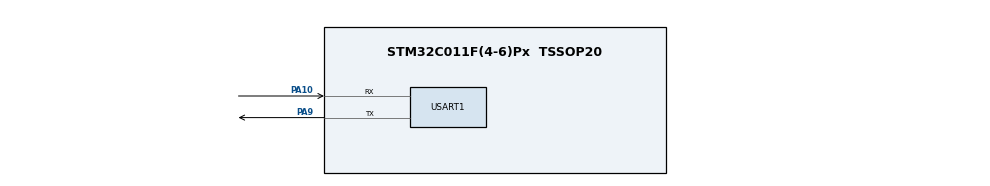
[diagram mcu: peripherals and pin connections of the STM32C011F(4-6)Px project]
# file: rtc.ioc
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Mcu.Family=STM32C0
Mcu.Name=STM32C011F(4-6)Px
Mcu.Package=TSSOP20
PA10\ [PA12].Mode=Asynchronous
PA10\ [PA12].Signal=USART1_RX
PA9\ [PA11].Mode=Asynchronous
PA9\ [PA11].Signal=USART1_TX
ProjectManager.HeapSize=0x200
ProjectManager.StackSize=0x400
ProjectManager.TargetToolchain=STM32CubeIDE
RCC.ADCFreq_Value=48000000
RCC.AHBFreq_Value=48000000
RCC.CortexFreq_Value=48000000
RCC.EXTERNAL_CLOCK_VALUE=12288000
RCC.HCLKFreq_Value=48000000
RCC.HSE_VALUE=8000000
RCC.HSISYSCLKDivider=RCC_HSI_DIV1
RCC.HSI_VALUE=48000000
RCC.SYSCLKFreq_VALUE=48000000
RTC.Format=RTC_FORMAT_BIN
USART1.VirtualMode-Asynchronous=VM_ASYNC
VP_RTC_VS_RTC_Activate.Mode=RTC_Enabled
VP_RTC_VS_RTC_Calendar.Mode=RTC_Calendar
VP_SYS_VS_PINREMAP.Mode=PINREMAP
VP_SYS_VS_PINREMAP_10_12.Mode=PINREMAP_10_12
board=custom

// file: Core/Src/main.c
/* USER CODE BEGIN Header */
/**
  ******************************************************************************
  * @file           : main.c
  * @brief          : Main program body
  ******************************************************************************
  * @attention
  *
  * Copyright (c) 2024 STMicroelectronics.
  * All rights reserved.
  *
  * This software is licensed under terms that can be found in the LICENSE file
  * in the root directory of this software component.
  * If no LICENSE file comes with this software, it is provided AS-IS.
  *
  ******************************************************************************
  */
/* USER CODE END Header */
#include "main.h"

/* USER CODE BEGIN Includes */
#include "stdio.h"
#include "string.h"
uint8_t dia, mes, ano, horas, segundos, minutos;
char uart_tx_buffer[50];

/* USER CODE END Includes */
RTC_HandleTypeDef hrtc;
UART_HandleTypeDef huart1;

/* USER CODE BEGIN PV */
RTC_DateTypeDef data;
RTC_TimeTypeDef tempo;
/* USER CODE END PV */
void SystemClock_Config(void);
static void MX_GPIO_Init(void);
static void MX_RTC_Init(void);
static void MX_USART1_UART_Init(void);
int main(void)
{
  /* MCU Configuration--------------------------------------------------------*/
  /* Reset of all peripherals, Initializes the Flash interface and the Systick. */
  HAL_Init();
  /* Configure the system clock */
  SystemClock_Config();
  /* Initialize all configured peripherals */
  MX_GPIO_Init();
  MX_RTC_Init();
  MX_USART1_UART_Init();
  /* USER CODE BEGIN 2 */
  /* Ajuste a data e a hora aqui */
   data.Year = 24;  // 2024
   data.Month = RTC_MONTH_JUNE;
   data.Date = 25;
   data.WeekDay = RTC_WEEKDAY_TUESDAY;
   tempo.Hours = 9;
   tempo.Minutes = 5;
   tempo.Seconds = 0;
   HAL_RTC_SetDate(&hrtc, &data, RTC_FORMAT_BIN);
   HAL_RTC_SetTime(&hrtc, &tempo, RTC_FORMAT_BIN);
  /* USER CODE END 2 */
  /* Infinite loop */
  while (1)
  {
    /* USER CODE BEGIN 3 */
	HAL_RTC_GetDate(&hrtc, &data, RTC_FORMAT_BIN);
	HAL_RTC_GetTime(&hrtc, &tempo, RTC_FORMAT_BIN);

	horas = tempo.Hours;
	minutos = tempo.Minutes;
	segundos = tempo.Seconds;
	dia = data.Date;
	mes = data.Month;
	ano = data.Year;
	sprintf(uart_tx_buffer, "Data: %02d/%02d/%04d Tempo: %02d:%02d:%02d\r\n", dia, mes, 2000+ano, horas, minutos, segundos);
	HAL_UART_Transmit(&huart1, (uint8_t *)uart_tx_buffer, strlen(uart_tx_buffer), 1000);
  }
  /* USER CODE END 3 */
}

void SystemClock_Config(void)
{
  RCC_OscInitTypeDef RCC_OscInitStruct = {0};
  RCC_ClkInitTypeDef RCC_ClkInitStruct = {0};

  /** Initializes the RCC Oscillators according to the specified parameters
  * in the RCC_OscInitTypeDef structure.
  */
  RCC_OscInitStruct.OscillatorType = RCC_OSCILLATORTYPE_HSI|RCC_OSCILLATORTYPE_LSI;
  RCC_OscInitStruct.HSIState = RCC_HSI_ON;
  RCC_OscInitStruct.HSIDiv = RCC_HSI_DIV1;
  RCC_OscInitStruct.HSICalibrationValue = RCC_HSICALIBRATION_DEFAULT;
  RCC_OscInitStruct.LSIState = RCC_LSI_ON;

  if (HAL_RCC_OscConfig(&RCC_OscInitStruct) != HAL_OK)
  {
    Error_Handler();
  }

  /** Initializes the CPU, AHB and APB buses clocks
  */
  RCC_ClkInitStruct.ClockType = RCC_CLOCKTYPE_HCLK|RCC_CLOCKTYPE_SYSCLK
                              |RCC_CLOCKTYPE_PCLK1;
  RCC_ClkInitStruct.SYSCLKSource = RCC_SYSCLKSOURCE_HSI;
  RCC_ClkInitStruct.SYSCLKDivider = RCC_SYSCLK_DIV1;
  RCC_ClkInitStruct.AHBCLKDivider = RCC_HCLK_DIV1;
  RCC_ClkInitStruct.APB1CLKDivider = RCC_APB1_DIV1;

  if (HAL_RCC_ClockConfig(&RCC_ClkInitStruct, FLASH_LATENCY_1) != HAL_OK)
  {
    Error_Handler();
  }
}

static void MX_RTC_Init(void)
{

  RTC_TimeTypeDef sTime = {0};
  RTC_DateTypeDef sDate = {0};

  /** Initialize RTC Only
  */
  hrtc.Instance = RTC;
  hrtc.Init.HourFormat = RTC_HOURFORMAT_24;
  hrtc.Init.AsynchPrediv = 127;
  hrtc.Init.SynchPrediv = 255;
  hrtc.Init.OutPut = RTC_OUTPUT_DISABLE;
  hrtc.Init.OutPutRemap = RTC_OUTPUT_REMAP_NONE;
  hrtc.Init.OutPutPolarity = RTC_OUTPUT_POLARITY_HIGH;
  hrtc.Init.OutPutType = RTC_OUTPUT_TYPE_OPENDRAIN;
  hrtc.Init.OutPutPullUp = RTC_OUTPUT_PULLUP_NONE;
  if (HAL_RTC_Init(&hrtc) != HAL_OK)
  {
    Error_Handler();
  }

  /** Initialize RTC and set the Time and Date
  */
  sTime.Hours = 0;
  sTime.Minutes = 0;
  sTime.Seconds = 0;
  sTime.SubSeconds = 0;
  sTime.DayLightSaving = RTC_DAYLIGHTSAVING_NONE;
  sTime.StoreOperation = RTC_STOREOPERATION_RESET;
  if (HAL_RTC_SetTime(&hrtc, &sTime, RTC_FORMAT_BIN) != HAL_OK)
  {
    Error_Handler();
  }
  sDate.WeekDay = RTC_WEEKDAY_MONDAY;
  sDate.Month = RTC_MONTH_JANUARY;
  sDate.Date = 1;
  sDate.Year = 0;

  if (HAL_RTC_SetDate(&hrtc, &sDate, RTC_FORMAT_BIN) != HAL_OK)
  {
    Error_Handler();
  }

}

static void MX_USART1_UART_Init(void)
{

  huart1.Instance = USART1;
  huart1.Init.BaudRate = 115200;
  huart1.Init.WordLength = UART_WORDLENGTH_8B;
  huart1.Init.StopBits = UART_STOPBITS_1;
  huart1.Init.Parity = UART_PARITY_NONE;
  huart1.Init.Mode = UART_MODE_TX_RX;
  huart1.Init.HwFlowCtl = UART_HWCONTROL_NONE;
  huart1.Init.OverSampling = UART_OVERSAMPLING_16;
  huart1.Init.OneBitSampling = UART_ONE_BIT_SAMPLE_DISABLE;
  huart1.Init.ClockPrescaler = UART_PRESCALER_DIV1;
  huart1.AdvancedInit.AdvFeatureInit = UART_ADVFEATURE_NO_INIT;
  if (HAL_UART_Init(&huart1) != HAL_OK)
  {
    Error_Handler();
  }
  if (HAL_UARTEx_SetTxFifoThreshold(&huart1, UART_TXFIFO_THRESHOLD_1_8) != HAL_OK)
  {
    Error_Handler();
  }
  if (HAL_UARTEx_SetRxFifoThreshold(&huart1, UART_RXFIFO_THRESHOLD_1_8) != HAL_OK)
  {
    Error_Handler();
  }
  if (HAL_UARTEx_DisableFifoMode(&huart1) != HAL_OK)
  {
    Error_Handler();
  }

}

static void MX_GPIO_Init(void)
{

  /* GPIO Ports Clock Enable */
  __HAL_RCC_GPIOA_CLK_ENABLE();

}

void Error_Handler(void)
{
  __disable_irq();
  while (1)
  {
  }
}
